# S32K148_M4 register map
Vendor: NXP Semiconductors; File version: 1.1
CPU: CM4 r0p1, little endian, MPU, FPU, VTOR, 4 interrupt priority bits
Registers are 32-bit, read-write, reset 0x0 unless marked. A register's access mark holds for its fields unless they carry their own. Offsets are from the block's base; [hi:lo] are bit positions; {n}, {i} and the like mark numbered series; 'fields as' and 'values as' point back to an identical list.

## PCC
Base 0x40065000
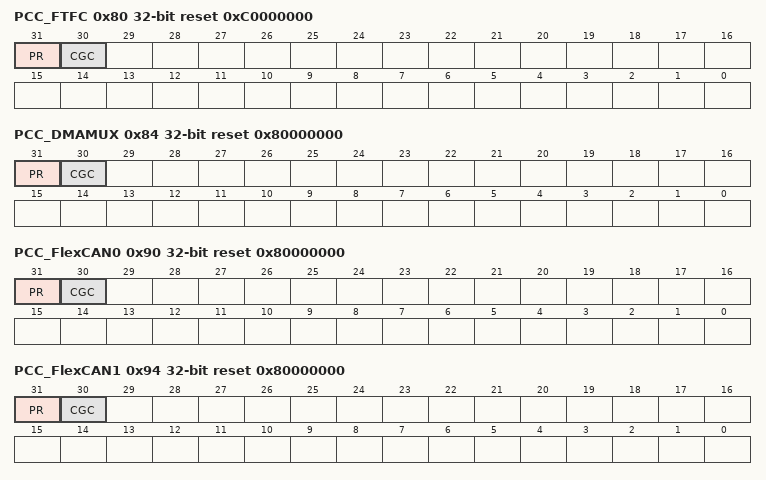
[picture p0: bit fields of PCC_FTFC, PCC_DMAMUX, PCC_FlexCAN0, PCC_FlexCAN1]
0x80 PCC_FTFC reset 0xC0000000
  [31] PR ro — Present
    0=NOT_PRESENT (Peripheral is not present.); 1=PRESENT (Peripheral is present.)
  [30] CGC — Clock Gate Control
    0=DISABLED (Clock disabled. The current clock selection and divider options are not locked and can be modified.); 1=ENABLED (Clock enabled. The current clock selection and divider options are locked and cannot be modified.)
0x84 PCC_DMAMUX reset 0x80000000
  fields as PCC_FTFC
0x90 PCC_FlexCAN0 reset 0x80000000
  fields as PCC_FTFC
0x94 PCC_FlexCAN1 reset 0x80000000
  fields as PCC_FTFC
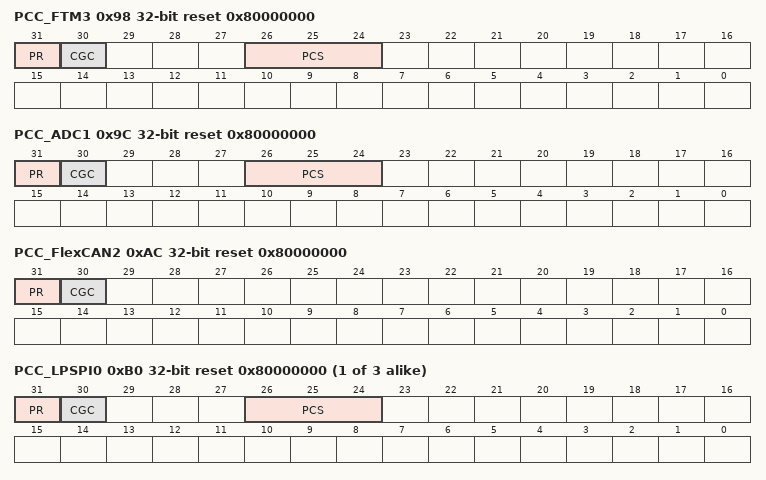
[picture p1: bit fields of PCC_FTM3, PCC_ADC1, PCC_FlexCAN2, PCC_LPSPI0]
0x98 PCC_FTM3 reset 0x80000000
  [31] PR ro — Present
    values as PCC_FTFC.PR
  [30] CGC — Clock Gate Control
    values as PCC_FTFC.CGC
  [26:24] PCS — Peripheral Clock Source Select
    0=CLOCK_EXT (Clock is off. An external clock can be enabled for this peripheral.); {v}=CLOCK_OPT{v} (Clock option {v}) (v=1..7)
0x9C PCC_ADC1 reset 0x80000000
  [31] PR ro — Present
    values as PCC_FTFC.PR
  [30] CGC — Clock Gate Control
    values as PCC_FTFC.CGC
  [26:24] PCS — Peripheral Clock Source Select
    0=CLOCK_OFF (Clock is off.); {v}=CLOCK_OPT{v} (Clock option {v}) (v=1..7)
0xAC PCC_FlexCAN2 reset 0x80000000
  fields as PCC_FTFC
{0xB0+4i} PCC_LPSPI{i} reset 0x80000000 (i=0..2)
  fields as PCC_ADC1
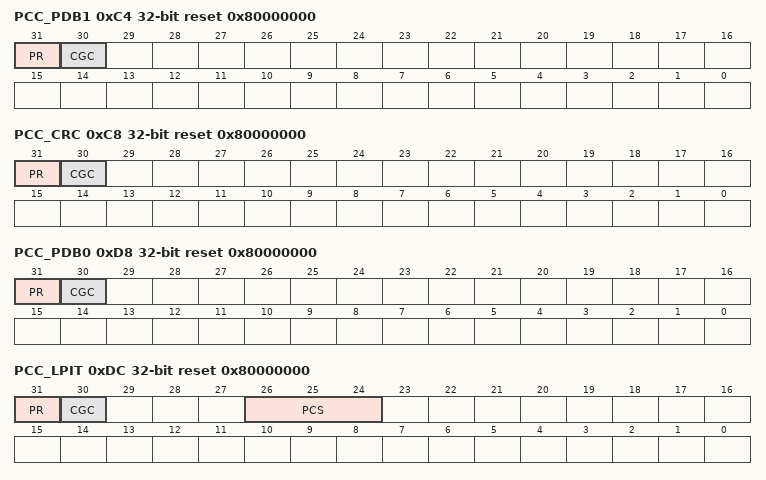
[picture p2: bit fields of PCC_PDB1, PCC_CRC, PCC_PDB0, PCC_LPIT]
0xC4 PCC_PDB1 reset 0x80000000
  fields as PCC_FTFC
0xC8 PCC_CRC reset 0x80000000
  fields as PCC_FTFC
0xD8 PCC_PDB0 reset 0x80000000
  fields as PCC_FTFC
0xDC PCC_LPIT reset 0x80000000
  fields as PCC_ADC1
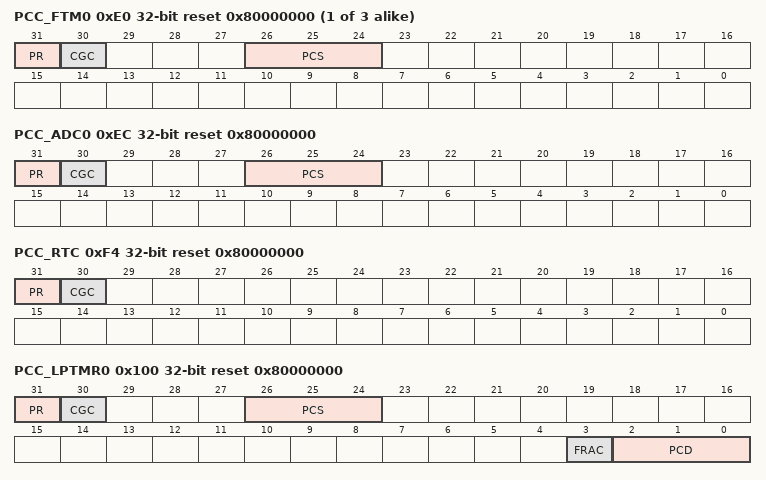
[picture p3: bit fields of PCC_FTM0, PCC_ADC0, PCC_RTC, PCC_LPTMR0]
{0xE0+4i} PCC_FTM{i} reset 0x80000000 (i=0..2)
  fields as PCC_FTM3
0xEC PCC_ADC0 reset 0x80000000
  fields as PCC_ADC1
0xF4 PCC_RTC reset 0x80000000
  fields as PCC_FTFC
0x100 PCC_LPTMR0 reset 0x80000000
  [31] PR ro — Present
    values as PCC_FTFC.PR
  [30] CGC — Clock Gate Control
    values as PCC_FTFC.CGC
  [26:24] PCS — Peripheral Clock Source Select
    values as PCC_ADC1.PCS
  [3] FRAC — Peripheral Clock Divider Fraction
    0=Fractional value is 0; 1=Fractional value is 1
  [2:0] PCD — Peripheral Clock Divider Select
    {v}=DIV_{v+1} (Divide by {v+1}.) (v=0..7)
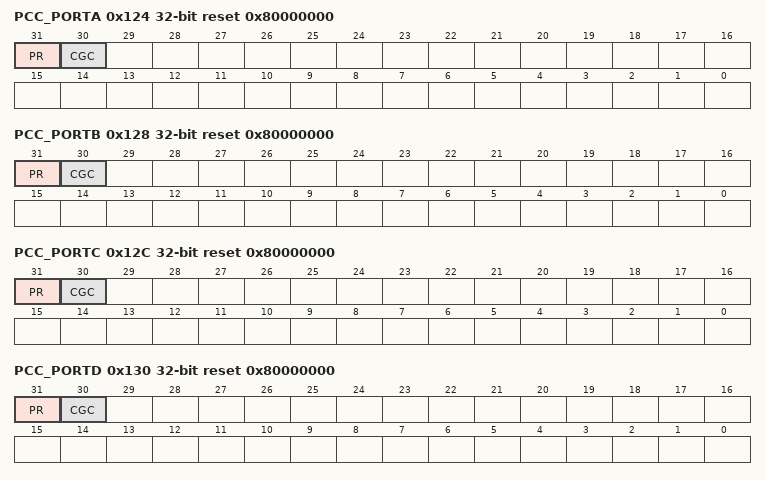
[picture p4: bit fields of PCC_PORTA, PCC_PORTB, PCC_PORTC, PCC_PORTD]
0x124 PCC_PORTA reset 0x80000000
  fields as PCC_FTFC
0x128 PCC_PORTB reset 0x80000000
  fields as PCC_FTFC
0x12C PCC_PORTC reset 0x80000000
  fields as PCC_FTFC
0x130 PCC_PORTD reset 0x80000000
  fields as PCC_FTFC
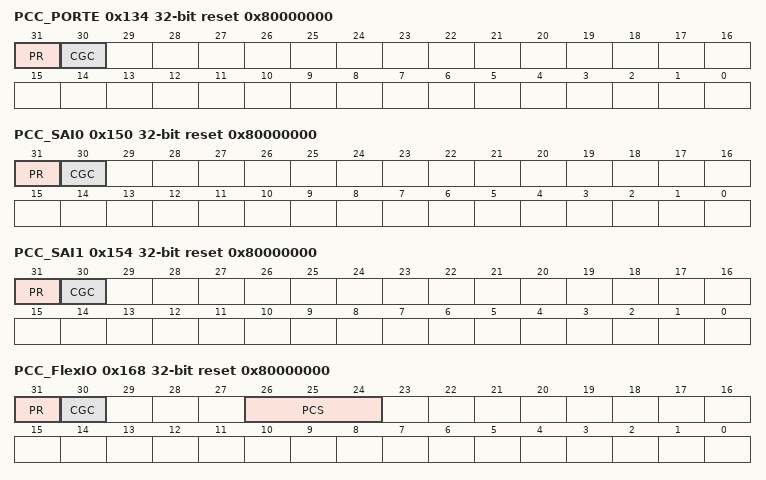
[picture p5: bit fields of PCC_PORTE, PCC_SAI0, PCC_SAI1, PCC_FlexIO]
0x134 PCC_PORTE reset 0x80000000
  fields as PCC_FTFC
0x150 PCC_SAI0 reset 0x80000000
  fields as PCC_FTFC
0x154 PCC_SAI1 reset 0x80000000
  fields as PCC_FTFC
0x168 PCC_FlexIO reset 0x80000000
  fields as PCC_ADC1
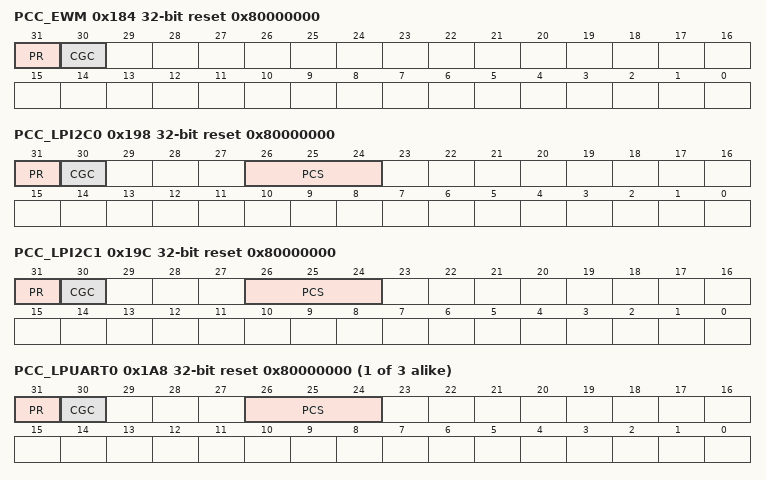
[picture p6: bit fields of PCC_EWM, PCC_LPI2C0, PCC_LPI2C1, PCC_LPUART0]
0x184 PCC_EWM reset 0x80000000
  fields as PCC_FTFC
0x198 PCC_LPI2C0 reset 0x80000000
  fields as PCC_ADC1
0x19C PCC_LPI2C1 reset 0x80000000
  fields as PCC_ADC1
{0x1A8+4i} PCC_LPUART{i} reset 0x80000000 (i=0..2)
  fields as PCC_ADC1
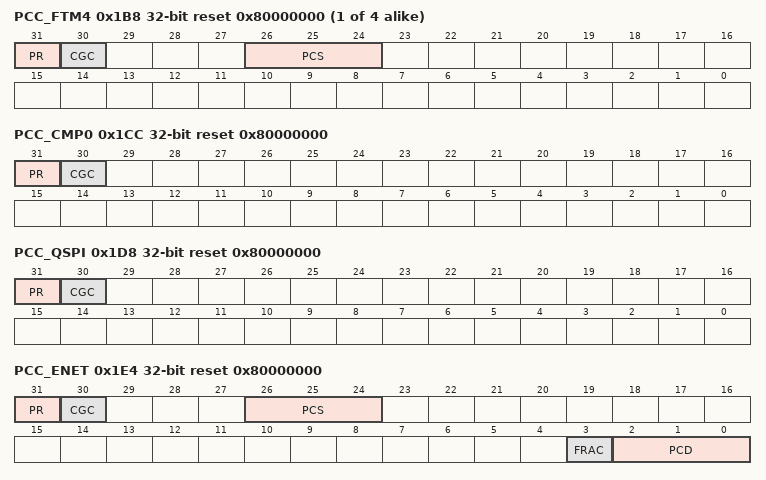
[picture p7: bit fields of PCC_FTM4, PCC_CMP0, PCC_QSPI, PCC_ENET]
{0x1A8+4i} PCC_FTM{i} reset 0x80000000 (i=4..7)
  fields as PCC_FTM3
0x1CC PCC_CMP0 reset 0x80000000
  fields as PCC_FTFC
0x1D8 PCC_QSPI reset 0x80000000
  fields as PCC_FTFC
0x1E4 PCC_ENET reset 0x80000000
  fields as PCC_LPTMR0

## PMC
Base 0x4007D000
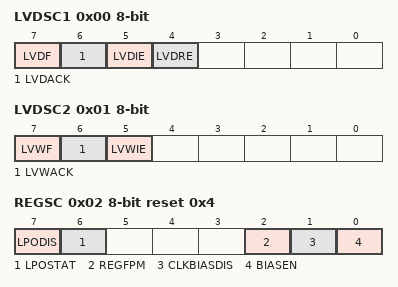
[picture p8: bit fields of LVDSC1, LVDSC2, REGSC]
0x00 LVDSC1 8-bit (reset mask 0xEF) — Low Voltage Detect Status and Control 1 Register
  [7] LVDF ro — Low Voltage Detect Flag
    0=Low-voltage event not detected; 1=Low-voltage event detected
  [6] LVDACK wo — Low Voltage Detect Acknowledge
  [5] LVDIE — Low Voltage Detect Interrupt Enable
    0=Hardware interrupt disabled (use polling); 1=Request a hardware interrupt when LVDF = 1
  [4] LVDRE — Low Voltage Detect Reset Enable
    0=No system resets on low voltage detect events; 1=If the supply voltage falls below VLVD, a system reset will be generated
0x01 LVDSC2 8-bit — Low Voltage Detect Status and Control 2 Register
  [7] LVWF ro — Low-Voltage Warning Flag
    0=Low-voltage warning event not detected; 1=Low-voltage warning event detected
  [6] LVWACK wo — Low-Voltage Warning Acknowledge
  [5] LVWIE — Low-Voltage Warning Interrupt Enable
    0=Hardware interrupt disabled (use polling); 1=Request a hardware interrupt when LVWF=1
0x02 REGSC 8-bit reset 0x4 (reset mask 0xBF) — Regulator Status and Control Register
  [7] LPODIS — LPO Disable Bit
    0=Low power oscillator enabled; 1=Low power oscillator disabled
  [6] LPOSTAT ro — LPO Status Bit
    0=Low power oscillator in low phase; 1=Low power oscillator in high phase
  [2] REGFPM ro — Regulator in Full Performance Mode Status Bit
    0=Regulator is in low power mode or transition to/from; 1=Regulator is in full performance mode
  [1] CLKBIASDIS — Clock Bias Disable Bit
    0=No effect; 1=In VLPS mode, the bias currents and reference voltages for the following clock modules are disabled: SIRC, FIRC, PLL. (if available on device)
  [0] BIASEN — Bias Enable Bit
    0=Biasing disabled, core logic can run in full performance; 1=Biasing enabled, core logic is slower and there are restrictions in allowed system clock speed (see Data Sheet for details)
0x04 LPOTRIM 8-bit (reset mask 0xE0) — Low Power Oscillator Trim Register
  [4:0] LPOTRIM — LPO trimming bits
